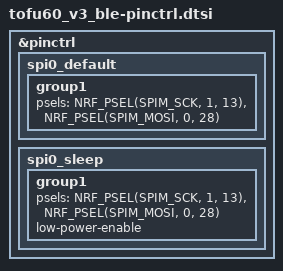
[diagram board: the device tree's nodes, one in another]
// SPDX-License-Identifier: MIT

&pinctrl {

  spi0_default: spi0_default {
    group1 {
      psels
        = <NRF_PSEL(SPIM_SCK, 1, 13)>
        , <NRF_PSEL(SPIM_MOSI, 0, 28)>
        ;
    };
  };

  spi0_sleep: spi0_sleep {
    group1 {
      psels
        = <NRF_PSEL(SPIM_SCK, 1, 13)>
        ,<NRF_PSEL(SPIM_MOSI, 0, 28)>
        ;
      low-power-enable;
    };
  };
};
